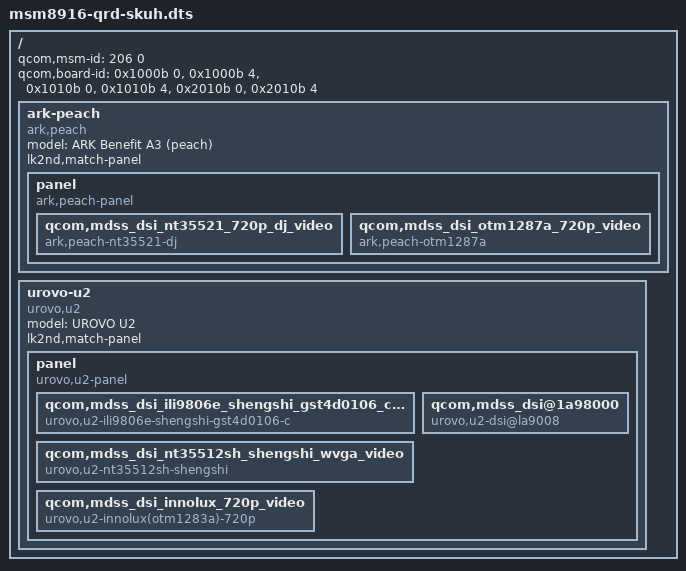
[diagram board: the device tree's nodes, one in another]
// SPDX-License-Identifier: GPL-2.0-only

/dts-v1/;

#include <skeleton.dtsi>

/ {
	// This is used by the bootloader to find the correct DTB
	qcom,msm-id = <206 0>;
	qcom,board-id = <0x1000b 0>, <0x1000b 4>, <0x1010b 0>, <0x1010b 4>,
			<0x2010b 0>, <0x2010b 4>;
	ark-peach {
		model = "ARK Benefit A3 (peach)";
		compatible = "ark,peach", "qcom,msm8916", "lk2nd,device";
		lk2nd,match-panel;

		panel {
			compatible = "ark,peach-panel";
			qcom,mdss_dsi_nt35521_720p_dj_video {
				compatible = "ark,peach-nt35521-dj";
			};
			qcom,mdss_dsi_otm1287a_720p_video {
				compatible = "ark,peach-otm1287a";
		};
	};
		
};
	urovo-u2 {
		model = "UROVO U2";
		compatible = "urovo,u2", "qcom,msm8916", "lk2nd,device";
		lk2nd,match-panel;

		panel {
			compatible = "urovo,u2-panel";

			qcom,mdss_dsi_ili9806e_shengshi_gst4d0106_c_wvga_video {
				compatible = "urovo,u2-ili9806e-shengshi-gst4d0106-c";
						};
			qcom,mdss_dsi_nt35512sh_shengshi_wvga_video {
				compatible = "urovo,u2-nt35512sh-shengshi";
					};
			qcom,mdss_dsi@1a98000 {
				compatible = "urovo,u2-dsi@la9008";
				};
			qcom,mdss_dsi_innolux_720p_video {
				compatible = "urovo,u2-innolux(otm1283a)-720p";
			};
		};
	};
};
